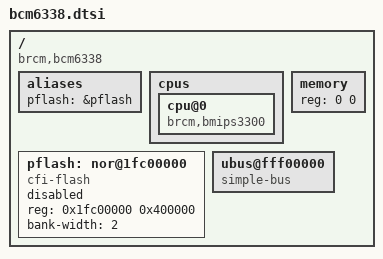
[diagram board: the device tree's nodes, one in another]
/ {
	#address-cells = <1>;
	#size-cells = <1>;
	compatible = "brcm,bcm6338";

	aliases {
		pflash = &pflash;
	};

	cpus {
		cpu@0 {
			compatible = "brcm,bmips3300", "mips,mips4Kc";
		};
	};

	memory { device_type = "memory"; reg = <0 0>; };

	pflash: nor@1fc00000 {
		compatible = "cfi-flash";
		reg = <0x1fc00000 0x400000>;
		bank-width = <2>;
		#address-cells = <1>;
		#size-cells = <1>;

		status = "disabled";
	};

	ubus@fff00000 {
		#address-cells = <1>;
		#size-cells = <1>;
		compatible = "simple-bus";
	};
};
